# STM32L4P5xx register map
File version: 1.0
Registers are 32-bit, read-write, reset 0x0 unless marked. A register's access mark holds for its fields unless they carry their own. Offsets are from the block's base; [hi:lo] are bit positions.

## CRS — Clock Recovery System
Base 0x40006000
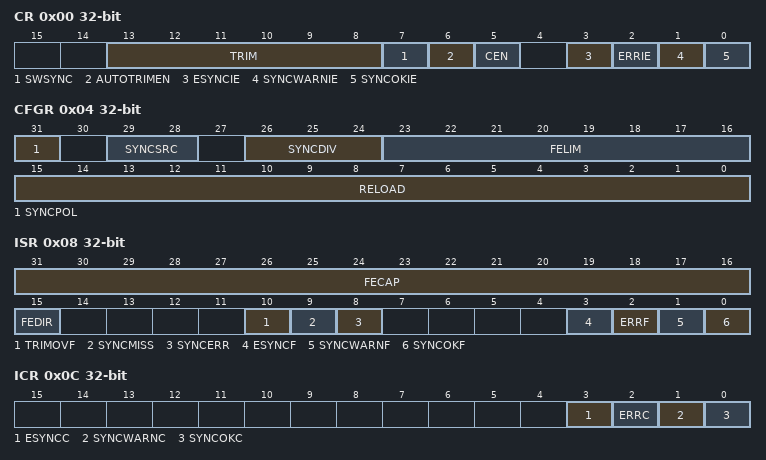
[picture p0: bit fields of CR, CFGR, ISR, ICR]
0x00 CR — CRS ccontrol register
  [13:8] TRIM — TRIM[5:0] HSI48 oscillator smooth trimming
  [7] SWSYNC — Generate software SYNC event
  [6] AUTOTRIMEN — Automatic trimming enable
  [5] CEN — Frequency error counter enable
  [3] ESYNCIE — Expected SYNC interrupt enable
  [2] ERRIE — SYNC error or trimming error interrupt enable
  [1] SYNCWARNIE — SYNC warning interrupt enable
  [0] SYNCOKIE — SYNC event OK interrupt enable
0x04 CFGR — CRS configuration register
  [31] SYNCPOL — SYNC polarity selection
    0=RISING (Synchro Active on rising edge (default)); 1=FALLING (Synchro Active on falling edge)
  [29:28] SYNCSRC — SYNC signal source selection
    0=GPIO (Synchro Signal source GPIO); 1=LSE (Synchro Signal source LSE); 2=USB (Synchro Signal source USB SOF (default))
  [26:24] SYNCDIV — SYNC divider
    0=DIV_1 (Synchro Signal not divided (default)); 1=DIV_2 (Synchro Signal divided by 2); 2=DIV_4 (Synchro Signal divided by 4); 3=DIV_8 (Synchro Signal divided by 8); 4=DIV_16 (Synchro Signal divided by 16); 5=DIV_32 (Synchro Signal divided by 32); 6=DIV_64 (Synchro Signal divided by 64); 7=DIV_128 (Synchro Signal divided by 128)
  [23:16] FELIM — Frequency error limit
  [15:0] RELOAD — Counter reload value
0x08 ISR — CRS interrupt and status register
  [31:16] FECAP — Frequency error capture
  [15] FEDIR — Frequency error direction
    0=UP (Upcounting direction, the actual frequency is above the target); 1=DOWN (Downcounting direction, the actual frequency is below the target)
  [10] TRIMOVF — Trimming overflow or underflow
  [9] SYNCMISS — SYNC missed
  [8] SYNCERR — SYNC error
  [3] ESYNCF — Expected SYNC flag
  [2] ERRF — Error flag
  [1] SYNCWARNF — SYNC warning flag
  [0] SYNCOKF — SYNC event OK flag
0x0C ICR — CRS interrupt flag clear register
  [3] ESYNCC — Expected SYNC clear flag
  [2] ERRC — Error clear flag
  [1] SYNCWARNC — SYNC warning clear flag
  [0] SYNCOKC — SYNC event OK clear flag

## OPAMP — Operational Amplifier (OPAMP)
Base 0x40007800
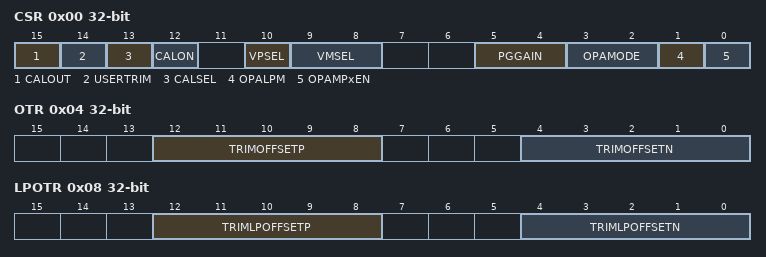
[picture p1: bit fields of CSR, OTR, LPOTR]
0x00 CSR — OPAMP control/status register
  [15] CALOUT — Operational amplifier1 calibration output
  [14] USERTRIM — User trimming enable
    0=FACTORY (OPAMP trimming factors set to factory values); 1=USER (OPAMP trimming factors set to user values)
  [13] CALSEL — Calibration selection
  [12] CALON — Calibration mode enable
    0=FUNCTIONAL (OPAMP functional mode); 1=CALIBRATION (OPAMP calibration mode)
  [10] VPSEL — Non inverted input selection
    0=NONINVERT_IO0 (OPAMP non inverting input connected to GPIO pin (pin PA0 for OPAMP1, pin PA6 for OPAMP2)); 1=NONINV_DAC1_CH1 (OPAMP non inverting input connected to DAC1 channel1 output)
  [9:8] VMSEL — Inverting input selection
    0=IO0 (OPAMP inverting input connected to GPIO pin (valid also in PGA mode for filtering). Note: OPAMP inverting input is used with OPAMP in mode standalone or PGA with external capacitors for filtering circuit. Otherwise (OPAMP in mode follower), OPAMP inverting input is not used (not connected to GPIO pin).); 1=IO1 (OPAMP inverting input (low leakage input) connected to GPIO pin (available only on package BGA132). Note: OPAMP inverting input is used with OPAMP in mode standalone or PGA with external capacitors for filtering circuit. Otherwise (OPAMP in mode follower), OPAMP inverting input is not used (not connected to GPIO pin).); 2=CONNECT_NO (OPAMP inverting input not externally connected (intended for OPAMP in mode follower or PGA without external capacitors for filtering))
  [5:4] PGGAIN — Operational amplifier Programmable amplifier gain value
    0=GAIN_2 (OPAMP PGA gain 2); 1=GAIN_4 (OPAMP PGA gain 4); 2=GAIN_8 (OPAMP PGA gain 8); 3=GAIN_16 (OPAMP PGA gain 16)
  [3:2] OPAMODE — Operational amplifier PGA mode
    0=STANDALONE (OPAMP functional mode, OPAMP operation in standalone); 3=FOLLOWER (OPAMP functional mode, OPAMP operation in follower); 2=PGA (OPAMP functional mode, OPAMP operation in PGA)
  [1] OPALPM — Operational amplifier Low Power Mode
  [0] OPAMPxEN — OPAMP enable
0x04 OTR — OPAMP
  [12:8] TRIMOFFSETP — Trim for PMOS differential pairs
  [4:0] TRIMOFFSETN — Trim for NMOS differential pairs
0x08 LPOTR — OPAMP
  [12:8] TRIMLPOFFSETP — Trim for PMOS differential pairs
  [4:0] TRIMLPOFFSETN — Trim for NMOS differential pairs
